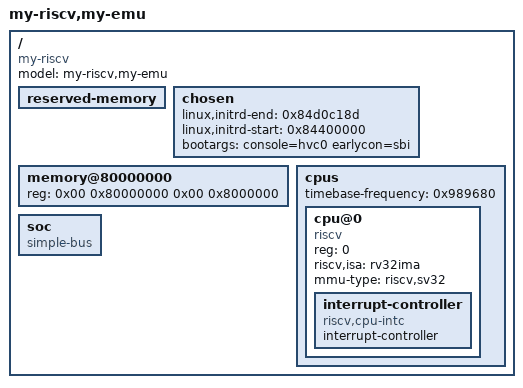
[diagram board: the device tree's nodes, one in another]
/dts-v1/;

/ {
	#address-cells = <2>;
	#size-cells = <2>;
	compatible = "my-riscv";
	model = "my-riscv,my-emu";

	reserved-memory {
		#address-cells = <2>;
		#size-cells = <2>;
		ranges;
	};

	chosen {
		linux,initrd-end = <0x84d0c18d>;
		linux,initrd-start = <0x84400000>;
		bootargs = "console=hvc0 earlycon=sbi";
	};

	memory@80000000 {
		device_type = "memory";
		reg = <0x00 0x80000000 0x00 0x8000000>;
	};

	cpus {
		#address-cells = <1>;
		#size-cells = <0>;
		timebase-frequency = <0x989680>;

		cpu@0 {
			device_type = "cpu";
			reg = <0>;
			status = "okay";
			compatible = "riscv";
			riscv,isa = "rv32ima";
			mmu-type = "riscv,sv32";

			interrupt-controller {
				#interrupt-cells = <1>;
				interrupt-controller;
				compatible = "riscv,cpu-intc";
			};
		};
	};

	soc {
		#address-cells = <2>;
		#size-cells = <2>;
		ranges;
		compatible = "simple-bus";
	};
};
